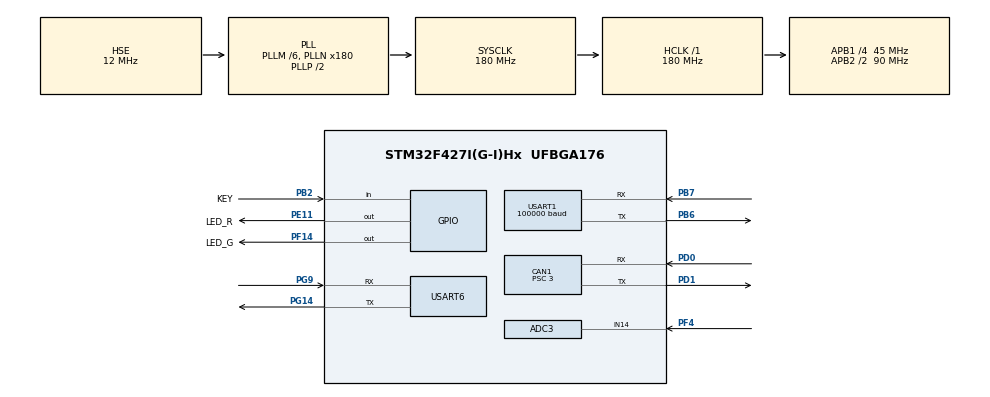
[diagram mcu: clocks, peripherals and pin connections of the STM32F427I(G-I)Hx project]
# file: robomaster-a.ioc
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ADC1.Channel-0\#ChannelRegularConversion=ADC_CHANNEL_VREFINT
ADC1.NbrOfConversionFlag=1
ADC1.Rank-0\#ChannelRegularConversion=1
ADC1.SamplingTime-0\#ChannelRegularConversion=ADC_SAMPLETIME_3CYCLES
ADC1.master=1
ADC3.Channel-0\#ChannelRegularConversion=ADC_CHANNEL_14
ADC3.NbrOfConversionFlag=1
ADC3.Rank-0\#ChannelRegularConversion=1
ADC3.SamplingTime-0\#ChannelRegularConversion=ADC_SAMPLETIME_3CYCLES
CAN1.BS1=CAN_BS1_10TQ
CAN1.BS2=CAN_BS2_4TQ
CAN1.CalculateBaudRate=1000000
CAN1.CalculateTimeBit=1000
CAN1.CalculateTimeQuantum=66.66666666666666
CAN1.Prescaler=3
Dma.Request0=USART1_RX
Dma.USART1_RX.0.Direction=DMA_PERIPH_TO_MEMORY
Dma.USART1_RX.0.FIFOMode=DMA_FIFOMODE_DISABLE
Dma.USART1_RX.0.Instance=DMA2_Stream2
Dma.USART1_RX.0.MemDataAlignment=DMA_MDATAALIGN_BYTE
Dma.USART1_RX.0.MemInc=DMA_MINC_ENABLE
Dma.USART1_RX.0.Mode=DMA_CIRCULAR
Dma.USART1_RX.0.PeriphDataAlignment=DMA_PDATAALIGN_BYTE
Dma.USART1_RX.0.PeriphInc=DMA_PINC_DISABLE
Dma.USART1_RX.0.Priority=DMA_PRIORITY_VERY_HIGH
FREERTOS.Tasks01=Led,24,128,Led_Entry,Default,NULL,Dynamic,NULL,NULL;Index,24,128,Index_Entry,As external,NULL,Dynamic,NULL,NULL;Mixer,32,512,Mixer_Entry,As external,NULL,Dynamic,NULL,NULL
Mcu.Family=STM32F4
Mcu.Name=STM32F427I(G-I)Hx
Mcu.Package=UFBGA176
NVIC.DMA2_Stream2_IRQn=true\:5\:0\:false\:false\:true\:true\:false\:true\:true
NVIC.PriorityGroup=NVIC_PRIORITYGROUP_4
NVIC.TIM6_DAC_IRQn=true\:15\:0\:false\:false\:true\:false\:false\:true\:true
NVIC.TimeBase=TIM6_DAC_IRQn
NVIC.TimeBaseIP=TIM6
NVIC.USART1_IRQn=true\:5\:0\:false\:false\:true\:true\:true\:true\:true
PA13.Mode=Serial_Wire
PA13.Signal=SYS_JTMS-SWDIO
PA14.Mode=Serial_Wire
PA14.Signal=SYS_JTCK-SWCLK
PB2/BOOT1.GPIO_Label=KEY
PB2/BOOT1.GPIO_PuPd=GPIO_PULLUP
PB2/BOOT1.Signal=GPIO_Input
PB6.Mode=Asynchronous
PB6.Signal=USART1_TX
PB7.Mode=Asynchronous
PB7.Signal=USART1_RX
PD0.Mode=CAN_Activate
PD0.Signal=CAN1_RX
PD1.Mode=CAN_Activate
PD1.Signal=CAN1_TX
PE11.GPIO_Label=LED_R
PE11.PinState=GPIO_PIN_SET
PE11.Signal=GPIO_Output
PF14.GPIO_Label=LED_G
PF14.PinState=GPIO_PIN_SET
PF14.Signal=GPIO_Output
PF4.Mode=IN14
PF4.Signal=ADC3_IN14
PG14.Mode=Asynchronous
PG14.Signal=USART6_TX
PG9.Mode=Asynchronous
PG9.Signal=USART6_RX
PH0/OSC_IN.Mode=HSE-External-Oscillator
PH0/OSC_IN.Signal=RCC_OSC_IN
PH1/OSC_OUT.Mode=HSE-External-Oscillator
PH1/OSC_OUT.Signal=RCC_OSC_OUT
ProjectManager.HeapSize=0x200
ProjectManager.StackSize=0x400
ProjectManager.TargetToolchain=MDK-ARM V5.32
RCC.48MHZClocksFreq_Value=90000000
RCC.AHBFreq_Value=180000000
RCC.APB1CLKDivider=RCC_HCLK_DIV4
RCC.APB1Freq_Value=45000000
RCC.APB1TimFreq_Value=90000000
RCC.APB2CLKDivider=RCC_HCLK_DIV2
RCC.APB2Freq_Value=90000000
RCC.APB2TimFreq_Value=180000000
RCC.CortexFreq_Value=180000000
RCC.HCLKFreq_Value=180000000
RCC.HSE_VALUE=12000000
RCC.HSI_VALUE=16000000
RCC.LSE_VALUE=32768
RCC.PLLM=6
RCC.PLLN=180
RCC.PLLSourceVirtual=RCC_PLLSOURCE_HSE
RCC.SYSCLKFreq_VALUE=180000000
RCC.SYSCLKSource=RCC_SYSCLKSOURCE_PLLCLK
RCC.VCOOutputFreq_Value=360000000
USART1.BaudRate=100000
USART1.Parity=PARITY_EVEN
USART1.VirtualMode=VM_ASYNC
USART1.WordLength=WORDLENGTH_9B
USART6.VirtualMode=VM_ASYNC
VP_ADC1_Vref_Input.Mode=IN-Vrefint
VP_FREERTOS_VS_CMSIS_V2.Mode=CMSIS_V2
VP_SYS_VS_tim6.Mode=TIM6
board=custom

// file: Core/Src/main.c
/* USER CODE BEGIN Header */
/**
  ******************************************************************************
  * @file           : main.c
  * @brief          : Main program body
  ******************************************************************************
  * @attention
  *
  * Copyright (c) 2024 STMicroelectronics.
  * All rights reserved.
  *
  * This software is licensed under terms that can be found in the LICENSE file
  * in the root directory of this software component.
  * If no LICENSE file comes with this software, it is provided AS-IS.
  *
  ******************************************************************************
  */
/* USER CODE END Header */
#include "main.h"
#include "cmsis_os.h"
#include "adc.h"
#include "can.h"
#include "dma.h"
#include "usart.h"
#include "gpio.h"

void SystemClock_Config(void);
void MX_FREERTOS_Init(void);

int main(void)
{

  /* MCU Configuration--------------------------------------------------------*/

  /* Reset of all peripherals, Initializes the Flash interface and the Systick. */
  HAL_Init();

  /* Configure the system clock */
  SystemClock_Config();

  /* Initialize all configured peripherals */
  MX_GPIO_Init();
  MX_DMA_Init();
  MX_ADC1_Init();
  MX_ADC3_Init();
  MX_USART1_UART_Init();
  MX_CAN1_Init();
  MX_USART6_UART_Init();

  /* Init scheduler */
  osKernelInitialize();

  /* Call init function for freertos objects (in cmsis_os2.c) */
  MX_FREERTOS_Init();

  /* Start scheduler */
  osKernelStart();

  /* We should never get here as control is now taken by the scheduler */

  /* Infinite loop */
  while (1)
  {

  }
}

void SystemClock_Config(void)
{
  RCC_OscInitTypeDef RCC_OscInitStruct = {0};
  RCC_ClkInitTypeDef RCC_ClkInitStruct = {0};

  /** Configure the main internal regulator output voltage
  */
  __HAL_RCC_PWR_CLK_ENABLE();
  __HAL_PWR_VOLTAGESCALING_CONFIG(PWR_REGULATOR_VOLTAGE_SCALE1);

  /** Initializes the RCC Oscillators according to the specified parameters
  * in the RCC_OscInitTypeDef structure.
  */
  RCC_OscInitStruct.OscillatorType = RCC_OSCILLATORTYPE_HSE;
  RCC_OscInitStruct.HSEState = RCC_HSE_ON;
  RCC_OscInitStruct.PLL.PLLState = RCC_PLL_ON;
  RCC_OscInitStruct.PLL.PLLSource = RCC_PLLSOURCE_HSE;
  RCC_OscInitStruct.PLL.PLLM = 6;
  RCC_OscInitStruct.PLL.PLLN = 180;
  RCC_OscInitStruct.PLL.PLLP = RCC_PLLP_DIV2;
  RCC_OscInitStruct.PLL.PLLQ = 4;
  if (HAL_RCC_OscConfig(&RCC_OscInitStruct) != HAL_OK)
  {
    Error_Handler();
  }

  /** Activate the Over-Drive mode
  */
  if (HAL_PWREx_EnableOverDrive() != HAL_OK)
  {
    Error_Handler();
  }

  /** Initializes the CPU, AHB and APB buses clocks
  */
  RCC_ClkInitStruct.ClockType = RCC_CLOCKTYPE_HCLK|RCC_CLOCKTYPE_SYSCLK
                              |RCC_CLOCKTYPE_PCLK1|RCC_CLOCKTYPE_PCLK2;
  RCC_ClkInitStruct.SYSCLKSource = RCC_SYSCLKSOURCE_PLLCLK;
  RCC_ClkInitStruct.AHBCLKDivider = RCC_SYSCLK_DIV1;
  RCC_ClkInitStruct.APB1CLKDivider = RCC_HCLK_DIV4;
  RCC_ClkInitStruct.APB2CLKDivider = RCC_HCLK_DIV2;

  if (HAL_RCC_ClockConfig(&RCC_ClkInitStruct, FLASH_LATENCY_5) != HAL_OK)
  {
    Error_Handler();
  }
}

void HAL_TIM_PeriodElapsedCallback(TIM_HandleTypeDef *htim)
{
  if (htim->Instance == TIM6) {
    HAL_IncTick();
  }
}

void Error_Handler(void)
{
  __disable_irq();
  while (1)
  {
  }
}

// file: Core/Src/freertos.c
/* USER CODE BEGIN Header */
/**
  ******************************************************************************
  * File Name          : freertos.c
  * Description        : Code for freertos applications
  ******************************************************************************
  * @attention
  *
  * Copyright (c) 2024 STMicroelectronics.
  * All rights reserved.
  *
  * This software is licensed under terms that can be found in the LICENSE file
  * in the root directory of this software component.
  * If no LICENSE file comes with this software, it is provided AS-IS.
  *
  ******************************************************************************
  */
/* USER CODE END Header */

#include "FreeRTOS.h"
#include "task.h"
#include "main.h"
#include "cmsis_os.h"

/* USER CODE BEGIN Includes */
#include "tp_thread.h"
#include "SEGGER_SYSVIEW.h"

/* USER CODE END Includes */

/* Definitions for Led */
osThreadId_t LedHandle;
const osThreadAttr_t Led_attributes = {
  .name = "Led",
  .stack_size = 128 * 4,
  .priority = (osPriority_t) osPriorityNormal,
};
/* Definitions for Index */
osThreadId_t IndexHandle;
const osThreadAttr_t Index_attributes = {
  .name = "Index",
  .stack_size = 128 * 4,
  .priority = (osPriority_t) osPriorityNormal,
};
/* Definitions for Mixer */
osThreadId_t MixerHandle;
const osThreadAttr_t Mixer_attributes = {
  .name = "Mixer",
  .stack_size = 512 * 4,
  .priority = (osPriority_t) osPriorityAboveNormal,
};

void Led_Entry(void *argument);
extern void Index_Entry(void *argument);
extern void Mixer_Entry(void *argument);

void MX_FREERTOS_Init(void); /* (MISRA C 2004 rule 8.1) */

void MX_FREERTOS_Init(void) {
  /* USER CODE BEGIN Init */
  SEGGER_SYSVIEW_Conf();

  /* USER CODE END Init */

  /* Create the thread(s) */
  /* creation of Led */
  LedHandle = osThreadNew(Led_Entry, NULL, &Led_attributes);

  /* creation of Index */
  IndexHandle = osThreadNew(Index_Entry, NULL, &Index_attributes);

  /* creation of Mixer */
  MixerHandle = osThreadNew(Mixer_Entry, NULL, &Mixer_attributes);

}

void Led_Entry(void *argument)
{
  /* USER CODE BEGIN Led_Entry */
  /* Infinite loop */
  for(;;)
  {
	LED_G_Toggle();
    osDelay(1000);
  }
  /* USER CODE END Led_Entry */
}
